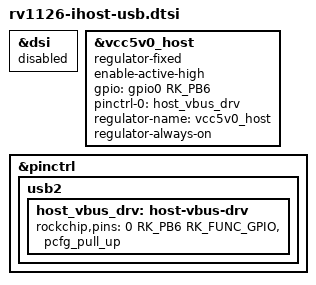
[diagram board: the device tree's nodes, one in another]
&dsi {
    status = "disabled";
};

&vcc5v0_host {
	compatible = "regulator-fixed";
	enable-active-high;
	gpio = <&gpio0 RK_PB6 GPIO_ACTIVE_HIGH>;
	pinctrl-names = "default";
	pinctrl-0 = <&host_vbus_drv>;
	regulator-name = "vcc5v0_host";
	regulator-always-on;
};


&pinctrl {
	 usb2 {
		host_vbus_drv: host-vbus-drv {
		rockchip,pins =
		<0 RK_PB6 RK_FUNC_GPIO &pcfg_pull_up>;
		};
	};
};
